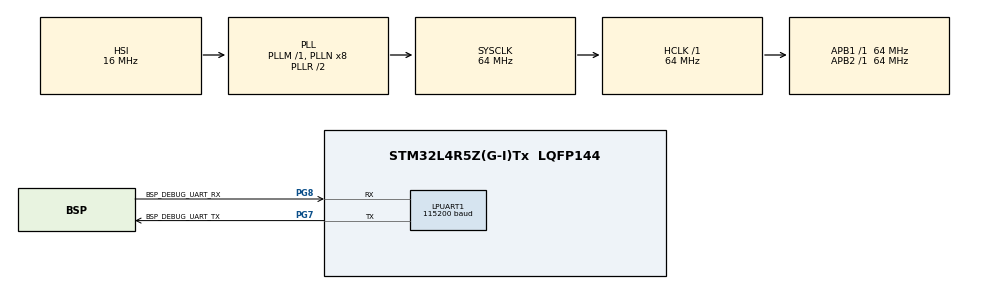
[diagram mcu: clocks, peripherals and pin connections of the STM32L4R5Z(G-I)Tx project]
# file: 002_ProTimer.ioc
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LPUART1.BaudRate=115200
LPUART1.WordLength=UART_WORDLENGTH_8B
Mcu.Family=STM32L4
Mcu.Name=STM32L4R5Z(G-I)Tx
Mcu.Package=LQFP144
NVIC.PriorityGroup=NVIC_PRIORITYGROUP_4
NVIC.TIM1_TRG_COM_TIM17_IRQn=true\:0\:0\:false\:false\:true\:true\:true\:true
PG7.GPIO_Label=BSP_DEBUG_UART_TX
PG7.Mode=Asynchronous
PG7.Signal=LPUART1_TX
PG8.GPIO_Label=BSP_DEBUG_UART_RX
PG8.Mode=Asynchronous
PG8.Signal=LPUART1_RX
ProjectManager.HeapSize=0x200
ProjectManager.StackSize=0x400
ProjectManager.TargetToolchain=STM32CubeIDE
RCC.48MHZClocksFreq_Value=24000000
RCC.ADCFreq_Value=64000000
RCC.AHBFreq_Value=64000000
RCC.APB1Freq_Value=64000000
RCC.APB1TimFreq_Value=64000000
RCC.APB2Freq_Value=64000000
RCC.APB2TimFreq_Value=64000000
RCC.CortexFreq_Value=64000000
RCC.HCLKFreq_Value=64000000
RCC.HSE_VALUE=8000000
RCC.HSI48_VALUE=48000000
RCC.HSI_VALUE=16000000
RCC.LSE_VALUE=32768
RCC.MSI_VALUE=4000000
RCC.PLLMUL=RCC_PLL_MUL9
RCC.PLLSourceVirtual=RCC_PLLSOURCE_HSI
RCC.PRESCALERUSB=RCC_USBCLKSOURCE_PLL_DIV1_5
RCC.SYSCLKFreq_VALUE=64000000
RCC.SYSCLKSource=RCC_SYSCLKSOURCE_PLLCLK
RCC.SYSCLKSourceVirtual=RCC_SYSCLKSOURCE_PLLCLK
RCC.USBFreq_Value=64000000
RCC.VCOOutputFreq_Value=128000000
TIM17.Period=1000-1
TIM17.Prescaler=64000-1
VP_TIM17_VS_ClockSourceINT.Mode=Enable_Timer
board=NUCLEO-L4R5ZI

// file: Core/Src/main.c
/* USER CODE BEGIN Header */
/**
  ******************************************************************************
  * @file           : main.c
  * @brief          : Main program body
  ******************************************************************************
  * @attention
  *
  * Copyright (c) 2024 STMicroelectronics.
  * All rights reserved.
  *
  * This software is licensed under terms that can be found in the LICENSE file
  * in the root directory of this software component.
  * If no LICENSE file comes with this software, it is provided AS-IS.
  *
  ******************************************************************************
  */
/* USER CODE END Header */
#include "main.h"

/* USER CODE BEGIN Includes */
#include "string.h"
#include "stdio.h"
/* USER CODE END Includes */

UART_HandleTypeDef hlpuart1;

TIM_HandleTypeDef htim17;

/* USER CODE BEGIN PV */
/* signals of the application */
typedef enum {
	INC_TIME,
	DEC_TIME,
	TIME_TICK,
	START_PAUSE,
	ABRT,
	/* Internal activity signals */
	ENTRY,
	EXIT
}protimer_signal_t;

/* various states of the application */
typedef enum{
	IDLE,
	TIME_SET,
	COUNTDOWN,
	PAUSE,
	STAT
}protimer_state_t;

/* main application struct */
typedef struct{
	uint32_t curr_time;
	uint32_t elapsed_time;
	uint32_t pro_time;
	protimer_state_t active_state;
}protimer_t;

/* generic(super) event structure */
typedef struct{
	uint8_t sig;
}event_t;

/* for user generated events */
typedef struct{
	event_t super;
}protimer_user_event_t;

/* for tick event */
typedef struct{
	event_t super;
	uint8_t ss;
}protimer_tick_event_t;

typedef enum{
	EVENT_HANDLED,
	EVENT_IGNORED,
	EVENT_TRANSITION
}event_status_t;

/* main application object */
protimer_t protimer;

//uint8_t Index = 0;
uint8_t rx_buffer;
//uint8_t data_buffer[2];
volatile uint32_t millis_counter = 0;

protimer_user_event_t ue;

static uint32_t current_time;

static protimer_tick_event_t te;

/* USER CODE END PV */

void SystemClock_Config(void);
static void MX_GPIO_Init(void);
static void MX_LPUART1_UART_Init(void);
static void MX_TIM17_Init(void);
/* USER CODE BEGIN PFP */
void protimer_init(protimer_t *mobj);
event_status_t protimer_state_machine(protimer_t *const mobj, event_t const *const e);
//prototypes of helper functions
static void display_clear(void);
static void display_message(char *string);
static void display_time(uint32_t time);

//prototypes of state handlers
static event_status_t protimer_state_handler_IDLE(protimer_t  *const mobj, event_t const *const e);
static event_status_t protimer_state_handler_TIME_SET(protimer_t  *const mobj, event_t const *const e);
static event_status_t protimer_state_handler_COUNTDOWN(protimer_t  *const mobj, event_t const *const e);
static event_status_t protimer_state_handler_PAUSE(protimer_t  *const mobj, event_t const *const e);
static event_status_t protimer_state_handler_STAT(protimer_t  *const mobj, event_t const *const e);

/* USER CODE END PFP */

/* USER CODE BEGIN 0 */
void protimer_init(protimer_t *mobj)
{
    event_t ee;
    ee.sig = ENTRY;
    mobj->active_state = IDLE;
    mobj->pro_time = 0;
    protimer_state_machine(mobj,&ee);
}

event_status_t protimer_state_machine(protimer_t *const mobj, event_t const *const e)
{
	switch (mobj->active_state) {
		case IDLE:{
			return protimer_state_handler_IDLE(mobj, e);
		}

		case TIME_SET:{
			return protimer_state_handler_TIME_SET(mobj, e);
		}

		case COUNTDOWN:{
			return protimer_state_handler_COUNTDOWN(mobj, e);
		}

		case PAUSE:{
			return protimer_state_handler_PAUSE(mobj, e);
		}

		case STAT:{
			return protimer_state_handler_STAT(mobj, e);
		}
	}
	return EVENT_IGNORED;
}

static event_status_t protimer_state_handler_IDLE(protimer_t *const mobj, event_t const *const e)
{
	switch (e->sig) {
		case ENTRY:{
			mobj->curr_time = 0;
			mobj->elapsed_time = 0;
			display_time(0);
			display_message("Set Time");
			return EVENT_HANDLED;
		}

		case EXIT:{
			display_clear();
			return EVENT_HANDLED;
		}

		case INC_TIME:{
			mobj->curr_time += 60;
			mobj->active_state = TIME_SET;
			return EVENT_TRANSITION;
		}

		case START_PAUSE:{
			mobj->active_state = STAT;
			return EVENT_TRANSITION;
		}

		case TIME_TICK:{
			if(((protimer_tick_event_t *)(e))->ss == 5)
			{
//				do_beep();
				return EVENT_HANDLED;
			}
			return EVENT_IGNORED;
		}
	}
	return EVENT_IGNORED;
}

static event_status_t protimer_state_handler_TIME_SET(protimer_t *const mobj, event_t const *const e){
    switch(e->sig){
        case ENTRY:{
            display_time(mobj->curr_time);
            return EVENT_HANDLED;
        }
        case EXIT:{
            display_clear();
            return EVENT_HANDLED;
        }
        case INC_TIME:{
            mobj->curr_time += 60;
            display_time(mobj->curr_time);
            return EVENT_HANDLED;
        }
        case DEC_TIME:{
            if(mobj->curr_time >=60){
                mobj->curr_time -= 60;
                display_time(mobj->curr_time);
                return EVENT_HANDLED;
            }
            return EVENT_IGNORED;
        }
        case ABRT:{
            mobj->active_state = IDLE;
            return EVENT_TRANSITION;
        }
        case START_PAUSE:{
            if(mobj->curr_time >=60){
                mobj->active_state = COUNTDOWN;
                return EVENT_TRANSITION;
            }
            return EVENT_IGNORED;
        }
    }

    return EVENT_IGNORED;
}

static event_status_t protimer_state_handler_COUNTDOWN(protimer_t *const mobj, event_t const *const e){
    switch(e->sig){
        case EXIT:{
            mobj->pro_time += mobj->elapsed_time;
            mobj->elapsed_time = 0;
            return EVENT_HANDLED;
        }

        case TIME_TICK:{
            if(((protimer_tick_event_t*)(e))->ss == 10){
                --mobj->curr_time;
                ++mobj->elapsed_time;
                display_time(mobj->curr_time);
                if(!mobj->curr_time){
                    mobj->active_state = IDLE;
                    return EVENT_TRANSITION;
                }
                return EVENT_HANDLED;
            }
            return EVENT_IGNORED;
        }
        case START_PAUSE:{
            mobj->active_state = PAUSE;
            return EVENT_TRANSITION;
        }
        case ABRT:{
            mobj->active_state = IDLE;
            return EVENT_TRANSITION;
        }
    }
    return EVENT_IGNORED;
}

static event_status_t protimer_state_handler_PAUSE(protimer_t *const mobj, event_t const *const e){
    switch(e->sig){
        case ENTRY:{
            display_message("Paused");
            return EVENT_HANDLED;
        }
        case EXIT:{
            display_clear();
            return EVENT_HANDLED;
        }
        case INC_TIME:{
            mobj->curr_time += 60;
            mobj->active_state = TIME_SET;
            return EVENT_TRANSITION;
        }
        case DEC_TIME:{
            if(mobj->curr_time >= 60){
                mobj->curr_time -= 60;
                mobj->active_state = TIME_SET;
                return EVENT_TRANSITION;
            }
            return EVENT_IGNORED;
        }
        case START_PAUSE:{
            mobj->active_state = COUNTDOWN;
            return EVENT_TRANSITION;
        }
        case ABRT:{
            mobj->active_state = IDLE;
            return EVENT_TRANSITION;
        }
    }
    return EVENT_IGNORED;
}

static event_status_t protimer_state_handler_STAT(protimer_t *const mobj, event_t const *const e){
    static uint8_t tick_count;

    switch(e->sig){
        case ENTRY:{
            display_time(mobj->pro_time);
            display_message("Productive time");
            return EVENT_HANDLED;
        }
        case EXIT:{
            display_clear();
            return EVENT_HANDLED;
        }
        case TIME_TICK:{
            if(++tick_count == 30){
                tick_count = 0;
                mobj->active_state = IDLE;
                return EVENT_TRANSITION;
            }
        }
    }
    return EVENT_IGNORED;
}

//////////////////////////helper functions//////////////////////////
static void display_time(uint32_t time){
  char buf[7];

  uint16_t m = time / 60;
  uint8_t s = time % 60;
  sprintf(buf,"%03d:%02d",m,s);

  printf("%s\r\n", buf);
}

static void display_message(char *string){
	printf("%s\r\n", string);
}

static void display_clear(void){
    printf("clear\r\n");
}

static void protimer_event_dispatcher(protimer_t *const mobj,event_t const *const e)
{

  event_status_t status;
  protimer_state_t source, target;

  source = mobj->active_state;
  status = protimer_state_machine(mobj,e);

  if(status == EVENT_TRANSITION){
    target = mobj->active_state;
    event_t ee;
    //1. run the exit action for the source state
    ee.sig = EXIT;
    mobj->active_state = source;
    protimer_state_machine(mobj,&ee);

    //2. run the entry action for the target state
    ee.sig = ENTRY;
    mobj->active_state = target;
    protimer_state_machine(mobj,&ee);
  }

}

void HAL_TIM_PeriodElapsedCallback(TIM_HandleTypeDef *htim)
{
	if(htim->Instance == TIM17)
	{
		millis_counter++;
	}
}

uint32_t millis(void)
{
	return millis_counter;
}
/* USER CODE END 0 */

int main(void)
{

  /* MCU Configuration--------------------------------------------------------*/

  /* Reset of all peripherals, Initializes the Flash interface and the Systick. */
  HAL_Init();

  /* Configure the system clock */
  SystemClock_Config();

  /* Initialize all configured peripherals */
  MX_GPIO_Init();
  MX_LPUART1_UART_Init();
  MX_TIM17_Init();
  /* USER CODE BEGIN 2 */

  protimer_init(&protimer);

  HAL_TIM_Base_Start_IT(&htim17);

  /* USER CODE END 2 */

  /* Infinite loop */
  while (1)
  {

    /* USER CODE BEGIN 3 */
//	  current_time = millis();

	  //2. make an event
	  if(HAL_UART_Receive(&hlpuart1, &rx_buffer, 1, HAL_MAX_DELAY) == HAL_OK)
	  {

		  if(rx_buffer == '1')
		  {
			  ue.super.sig = INC_TIME;
		  }
		  else if(rx_buffer == '2')
		  {
			  ue.super.sig = DEC_TIME;
		  }
		  else if(rx_buffer == '3')
		  {
			  ue.super.sig = START_PAUSE;
		  }
		  else if(rx_buffer == '4')
		  {
			  ue.super.sig = ABRT;
		  }

	     //3. send it to event dispatcher
	    protimer_event_dispatcher(&protimer,&ue.super);
	  }

	  //4. dispatch the time tick event for every 100ms
	  if(millis() - current_time  >= 100){
	    //100ms has passed
	    current_time = millis();
	    te.super.sig = TIME_TICK;
	    if(++te.ss > 10) te.ss = 1;
	    protimer_event_dispatcher(&protimer,&te.super);
	  }

  }
  /* USER CODE END 3 */
}

void SystemClock_Config(void)
{
  RCC_OscInitTypeDef RCC_OscInitStruct = {0};
  RCC_ClkInitTypeDef RCC_ClkInitStruct = {0};

  /** Configure the main internal regulator output voltage
  */
  if (HAL_PWREx_ControlVoltageScaling(PWR_REGULATOR_VOLTAGE_SCALE1) != HAL_OK)
  {
    Error_Handler();
  }

  /** Initializes the RCC Oscillators according to the specified parameters
  * in the RCC_OscInitTypeDef structure.
  */
  RCC_OscInitStruct.OscillatorType = RCC_OSCILLATORTYPE_HSI;
  RCC_OscInitStruct.HSIState = RCC_HSI_ON;
  RCC_OscInitStruct.HSICalibrationValue = RCC_HSICALIBRATION_DEFAULT;
  RCC_OscInitStruct.PLL.PLLState = RCC_PLL_ON;
  RCC_OscInitStruct.PLL.PLLSource = RCC_PLLSOURCE_HSI;
  RCC_OscInitStruct.PLL.PLLM = 1;
  RCC_OscInitStruct.PLL.PLLN = 8;
  RCC_OscInitStruct.PLL.PLLP = RCC_PLLP_DIV2;
  RCC_OscInitStruct.PLL.PLLQ = RCC_PLLQ_DIV2;
  RCC_OscInitStruct.PLL.PLLR = RCC_PLLR_DIV2;
  if (HAL_RCC_OscConfig(&RCC_OscInitStruct) != HAL_OK)
  {
    Error_Handler();
  }

  /** Initializes the CPU, AHB and APB buses clocks
  */
  RCC_ClkInitStruct.ClockType = RCC_CLOCKTYPE_HCLK|RCC_CLOCKTYPE_SYSCLK
                              |RCC_CLOCKTYPE_PCLK1|RCC_CLOCKTYPE_PCLK2;
  RCC_ClkInitStruct.SYSCLKSource = RCC_SYSCLKSOURCE_PLLCLK;
  RCC_ClkInitStruct.AHBCLKDivider = RCC_SYSCLK_DIV1;
  RCC_ClkInitStruct.APB1CLKDivider = RCC_HCLK_DIV1;
  RCC_ClkInitStruct.APB2CLKDivider = RCC_HCLK_DIV1;

  if (HAL_RCC_ClockConfig(&RCC_ClkInitStruct, FLASH_LATENCY_3) != HAL_OK)
  {
    Error_Handler();
  }
}

static void MX_LPUART1_UART_Init(void)
{

  hlpuart1.Instance = LPUART1;
  hlpuart1.Init.BaudRate = 115200;
  hlpuart1.Init.WordLength = UART_WORDLENGTH_8B;
  hlpuart1.Init.StopBits = UART_STOPBITS_1;
  hlpuart1.Init.Parity = UART_PARITY_NONE;
  hlpuart1.Init.Mode = UART_MODE_TX_RX;
  hlpuart1.Init.HwFlowCtl = UART_HWCONTROL_NONE;
  hlpuart1.Init.OneBitSampling = UART_ONE_BIT_SAMPLE_DISABLE;
  hlpuart1.Init.ClockPrescaler = UART_PRESCALER_DIV1;
  hlpuart1.AdvancedInit.AdvFeatureInit = UART_ADVFEATURE_NO_INIT;
  hlpuart1.FifoMode = UART_FIFOMODE_DISABLE;
  if (HAL_UART_Init(&hlpuart1) != HAL_OK)
  {
    Error_Handler();
  }
  if (HAL_UARTEx_SetTxFifoThreshold(&hlpuart1, UART_TXFIFO_THRESHOLD_1_8) != HAL_OK)
  {
    Error_Handler();
  }
  if (HAL_UARTEx_SetRxFifoThreshold(&hlpuart1, UART_RXFIFO_THRESHOLD_1_8) != HAL_OK)
  {
    Error_Handler();
  }
  if (HAL_UARTEx_DisableFifoMode(&hlpuart1) != HAL_OK)
  {
    Error_Handler();
  }

}

static void MX_TIM17_Init(void)
{

  htim17.Instance = TIM17;
  htim17.Init.Prescaler = 64000-1;
  htim17.Init.CounterMode = TIM_COUNTERMODE_UP;
  htim17.Init.Period = 100-1;
  htim17.Init.ClockDivision = TIM_CLOCKDIVISION_DIV1;
  htim17.Init.RepetitionCounter = 0;
  htim17.Init.AutoReloadPreload = TIM_AUTORELOAD_PRELOAD_DISABLE;
  if (HAL_TIM_Base_Init(&htim17) != HAL_OK)
  {
    Error_Handler();
  }

}

static void MX_GPIO_Init(void)
{

  /* GPIO Ports Clock Enable */
  __HAL_RCC_GPIOG_CLK_ENABLE();
  HAL_PWREx_EnableVddIO2();

}

void Error_Handler(void)
{
  __disable_irq();
  while (1)
  {
  }
}
